AUTOSAR XML (schema 00052)
package /Components
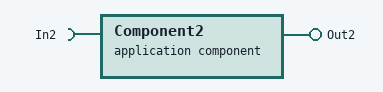
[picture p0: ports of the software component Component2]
  application sw component type Component2
    require port In2
    provide port Out2
